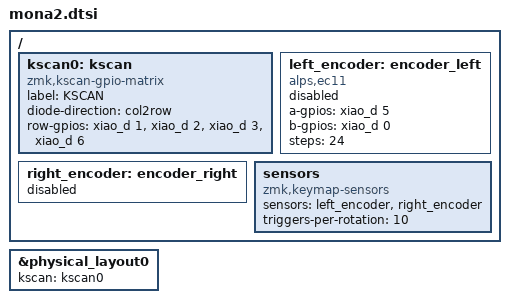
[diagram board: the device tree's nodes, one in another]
/* Hardware shared by the left and right halves (Seeed XIAO nRF52840). */
#include "mona2-common.dtsi"

/ {
    kscan0: kscan {
        compatible = "zmk,kscan-gpio-matrix";
        label = "KSCAN";
        diode-direction = "col2row";
            row-gpios
                = <&xiao_d 1 (GPIO_ACTIVE_HIGH | GPIO_PULL_DOWN)> 
                , <&xiao_d 2 (GPIO_ACTIVE_HIGH | GPIO_PULL_DOWN)> 
                , <&xiao_d 3 (GPIO_ACTIVE_HIGH | GPIO_PULL_DOWN)> 
                , <&xiao_d 6 (GPIO_ACTIVE_HIGH | GPIO_PULL_DOWN)> 			
                ;
    };

    left_encoder: encoder_left {
        compatible = "alps,ec11";
        a-gpios = <&xiao_d 5 (GPIO_ACTIVE_HIGH | GPIO_PULL_UP)>;
        b-gpios = <&xiao_d 0 (GPIO_ACTIVE_HIGH | GPIO_PULL_UP)>;
        steps = <24>;
        status = "disabled";
    };

    right_encoder: encoder_right {
        status = "disabled";
    };

    sensors: sensors {
        compatible = "zmk,keymap-sensors";
        sensors = <&left_encoder &right_encoder>;
        triggers-per-rotation = <10>;
    };

};

&physical_layout0 {
    kscan = <&kscan0>;
};
